CM_ "Toyota Yaris Hybrid 2014 (XP130, THS-II NoDSU) - reverse engineered from a candump (500kbps) captured on the";
CM_ "factory head-unit connector (28-pin, p/n 90980-12555, CAN-H=pin9/CAN-L=pin10), NOT the OBD-II diagnostic port.";
CM_ "Base messages taken from BogGyver/opendbc (tesla_unity_dev) toyota_nodsu_hybrid_pt_generated.dbc and empirically validated";
CM_ "against two independent real drive logs (re/data/logs/session_0044.log ~430s, session_0047.log ~440s). Additions for";
CM_ "BRAKE_ANALOG (0x224), COMBO_METER_0x34 (0x618), FUEL_COUNTER (0x3A0), HYBRID_STATUS/EV_DRIVE (0x498),";
CM_ "HV_BATTERY/BATTERY_SOC /BATTERY_CURRENT (0x49D), ICE_RUNNING (0x245 b3.4) and PWR_DEMAND (0x320) are original findings from this";
CM_ "project, not present in opendbc.";
CM_ "See re/docs/signal_findings.md for full validation methodology and confidence levels.";

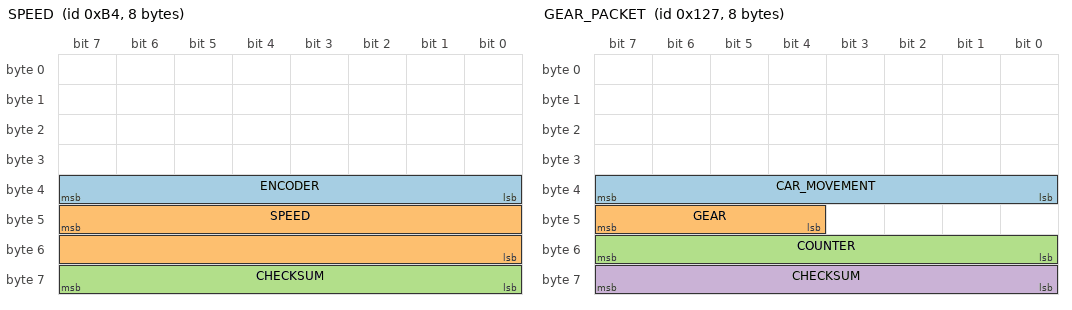
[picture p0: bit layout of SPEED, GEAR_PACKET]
BO_ 180 SPEED: 8 XXX
 SG_ ENCODER : 39|8@0+ (1,0) [0|255] "" XXX
 SG_ SPEED : 47|16@0+ (0.01,0) [0|250] "kph" XXX
 SG_ CHECKSUM : 63|8@0+ (1,0) [0|255] "" XXX

CM_ SG_ 180 SPEED "CONFIRMED. Validated against real 0->60->0 kph driving profile.";

BO_ 452 ENGINE_RPM: 8 XXX
 SG_ RPM : 7|16@0- (0.78125,0) [0|0] "rpm" XXX

CM_ SG_ 452 RPM "CONFIRMED. Oscillates 0/~1000-2000rpm matching ICE start/stop cycling typical of THS-II.";

BO_ 295 GEAR_PACKET: 8 XXX
 SG_ CAR_MOVEMENT : 39|8@0- (1,0) [0|255] "" XXX
 SG_ GEAR : 47|4@0+ (1,0) [0|15] "" XXX
 SG_ COUNTER : 55|8@0+ (1,0) [0|255] "" XXX
 SG_ CHECKSUM : 63|8@0+ (1,0) [0|255] "" XXX

VAL_ 295 GEAR 0 "P" 1 "R" 2 "N" 3 "D" 4 "B" ;
CM_ SG_ 295 GEAR "CONFIRMED, all 5 states observed across two independent logs: session_0044 shows a clean P(0)->R(1)->D(3) sequence with SPEED/BRAKE_PRESSED transitions lining up exactly with each shift; session_0047 adds N(2) and a full end-of-drive cycle through all five states including B (Engine Brake). CAR_MOVEMENT (byte4, signed) is a separate field in the same message, not part of the gear value.";

BO_ 560 BRAKE_MODULE2: 7 XXX
 SG_ BRAKE_PRESSED : 26|1@0+ (1,0) [0|1] "" XXX

CM_ SG_ 560 BRAKE_PRESSED "CONFIRMED. Transition timings correlate exactly with GEAR shifts and SPEED changes (brake held at standstill before/after each gear change).";

BO_ 548 BRAKE_ANALOG: 8 XXX
 SG_ BRAKE_VALUE : 32|16@0+ (1,0) [0|1023] "" XXX

CM_ BO_ 548 "STRONG HYPOTHESIS (not in any opendbc DBC). ID 0x224, ~41Hz. Formula: value = byte[4]<<8 | byte[5] (~10-bit, max observed 537). Median 0 while BRAKE_PRESSED=0 (n=12027) vs median 62 while pressed (n=5731); 99.99% of released samples <=5, 84% of pressed samples >5. Strong correlation confirms this is a brake pedal analog signal (pressure and/or position), but exact physical units/scale are NOT confirmed.";

BO_ 581 GAS_PEDAL: 8 XXX
 SG_ GAS_PEDAL : 23|8@0+ (0.005,0) [0|1] "" XXX
 SG_ ICE_RUNNING : 28|1@0+ (1,0) [0|1] "" XXX

CM_ SG_ 581 GAS_PEDAL "CONFIRMED. 0.0-0.35 (0-35%) range observed, closely tracking the accelerate/coast pattern of city driving and preceding each RPM/SPEED rise.";
CM_ SG_ 581 ICE_RUNNING "CONFIRMED on two independent logs. byte[3] bit4. 1 while the combustion engine is actually spinning (RPM>~800), 0 while stopped, INDEPENDENT of vehicle motion: 98-99% agreement with RPM(0x1C4)>50 across all four (moving/stopped x ICE on/off) states in both logs. Cleaner than thresholding RPM.";

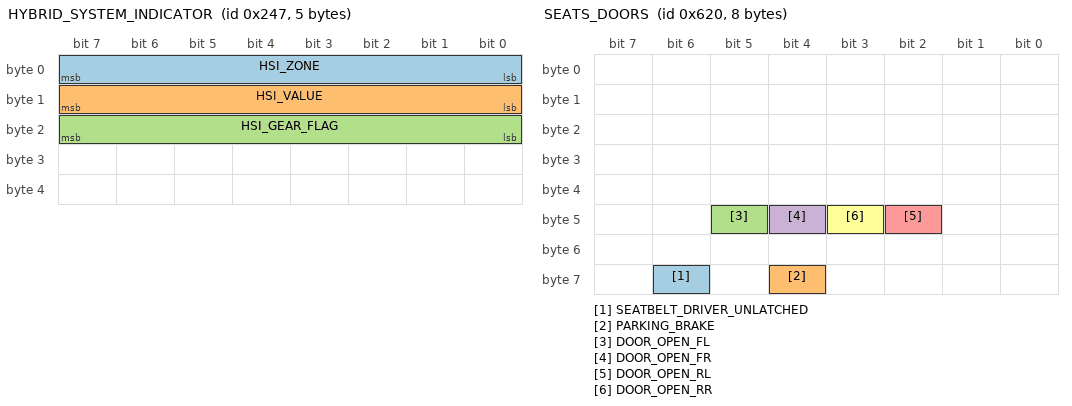
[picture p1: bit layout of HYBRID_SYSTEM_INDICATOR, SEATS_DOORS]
BO_ 583 HYBRID_SYSTEM_INDICATOR: 5 XXX
 SG_ HSI_ZONE : 7|8@0+ (1,0) [0|15] "" XXX
 SG_ HSI_VALUE : 15|8@0+ (1,0) [0|255] "%" XXX
 SG_ HSI_GEAR_FLAG : 23|8@0+ (1,0) [0|255] "" XXX

VAL_ 583 HSI_ZONE 4 "zero_in_gear" 6 "inactive_P_R" 12 "drive" 15 "charge" ;
VAL_ 583 HSI_GEAR_FLAG 50 "forward_gear" 255 "P_or_R" ;
CM_ BO_ 583 "CONFIRMED on two independent logs. ID 0x247, 42.5Hz, companion message of GAS_PEDAL (0x245). This is the dash CHG/ECO/PWR 'Hybrid System Indicator' value. HSI_VALUE (byte[1], sign per HSI_ZONE -- see SIGN NOTE below) = gauge position in percent of scale: 0 at standstill, +30..+47 at steady cruise (where the accel-like 0x320 byte4 sits at ~0 -- the discriminating test), up to +86/+94 observed under hard acceleration (full PWR = +100, never reached in these gentle drives), negative while coasting (-10..-19, light CHG) and braking, HARD-CLAMPED at -100 = full CHG. Always 0 in R and N, matching the real dash HSI which is inactive outside forward drive. HSI_ZONE (byte[0]): 12 on the PWR/ECO side, 15 on the CHG side, 4 when zero while in gear, 6 in P/R. HSI_GEAR_FLAG (byte[2]): 50 in forward gears, 255 in P/R. The exact ECO/PWR boundary is a fixed fraction of the positive scale on the real gauge (typically the top ~third); calibrate visually against the dash if pixel-exact zoning is needed. SIGN NOTE: HSI_ZONE, not HSI_VALUE's byte, carries the sign -- the two sides encode byte[1] differently and their raw ranges overlap. Zone 12 (PWR/ECO): byte[1] is an unsigned magnitude that sweeps past 155 under full throttle. Zone 15 (CHG): byte[1] is two's complement, hard-clamped at -100 (raw 156). Zones 4/6: always 0. The correlation is exact across both logs (n=32779). Inferring the sign from byte[1] alone -- either the DBC-nominal signed int8_t or the raw>=156 floor rule -- reads a hard-PWR value as deeply negative and swings the gauge to full CHG; confirmed on the car, hence the zone-based decode in firmware. DISPLAY NOTE: the dash halves the positive (PWR) value for display (PWR% = raw/2) because the ECO/PWR boundary (raw~100) is only the midpoint of the real gauge's PWR sweep, not its top -- see re/docs/signal_findings.md for the full caveat.";

BO_ 1090 CLIMATE_0x442: 8 XXX
 SG_ AMBIENT_TEMP : 7|8@0+ (1,-40) [-40|215] "degC" XXX

CM_ SG_ 1090 AMBIENT_TEMP "CONFIRMED. ID 0x442 (~2.5Hz, climate family 0x440/0x442/0x44D/0x45C), byte[0] - 40 = outside/ambient temperature in degC. The only byte that is quasi-constant (>95% single value) within each session but different across the two logs (raw 77 vs 67 -> 37degC vs 27degC); scale confirmed against the actual outside temperatures of the two capture days.";

BO_ 1553 UI_SETTING: 8 XXX
 SG_ UNITS : 26|2@0+ (1,0) [0|3] "" XXX
 SG_ ODOMETER : 43|20@0+ (1,0) [0|1048575] "" XXX

VAL_ 1553 UNITS 1 "km" 2 "miles" ;
CM_ SG_ 1553 ODOMETER "CONFIRMED but NOT remaining range. This is the TOTAL vehicle odometer (99552 -> 99555 km over the ~7min/~3km log, UNITS=km). No distance-to-empty / remaining-range signal was found on this bus -- see re/docs/signal_findings.md for the negative-result justification.";

BO_ 1556 STEERING_LEVERS: 8 XXX
 SG_ TURN_SIGNALS : 29|2@0+ (1,0) [0|3] "" XXX
 SG_ HAZARD_LIGHT : 27|1@0+ (1,0) [0|1] "" XXX

VAL_ 1556 TURN_SIGNALS 3 "none" 2 "right" 1 "left" ;
CM_ SG_ 1556 TURN_SIGNALS "CONFIRMED. All 3 states (left/right/none) observed over the drive with plausible multi-second durations consistent with real indicator usage at turns.";

BO_ 1568 SEATS_DOORS: 8 XXX
 SG_ SEATBELT_DRIVER_UNLATCHED : 62|1@0+ (1,0) [0|1] "" XXX
 SG_ PARKING_BRAKE : 60|1@0+ (1,0) [0|1] "" XXX
 SG_ DOOR_OPEN_FL : 45|1@0+ (1,0) [0|1] "" XXX
 SG_ DOOR_OPEN_FR : 44|1@0+ (1,0) [0|1] "" XXX
 SG_ DOOR_OPEN_RL : 42|1@0+ (1,0) [0|1] "" XXX
 SG_ DOOR_OPEN_RR : 43|1@0+ (1,0) [0|1] "" XXX

CM_ BO_ 1568 "CONFIRMED PRESENT, plausible (seatbelt toggles 0/1); doors never opened during this particular drive so DOOR_OPEN_* only show constant 0 in this log (not independently validated, but the message/bit layout is inherited verbatim from opendbc).";

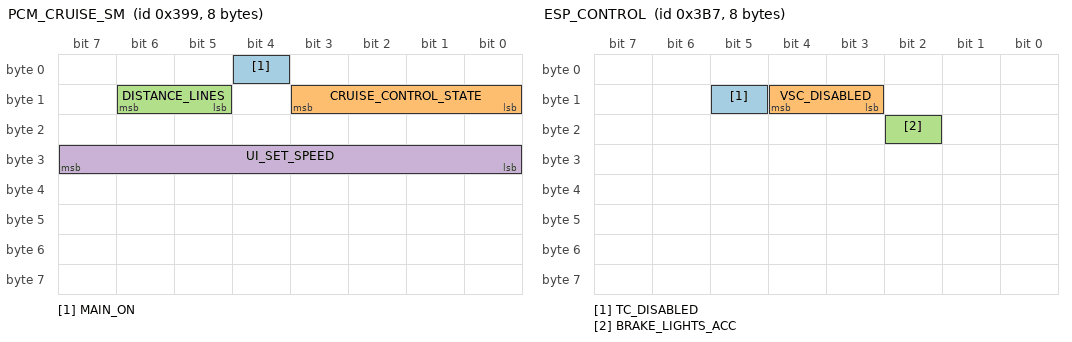
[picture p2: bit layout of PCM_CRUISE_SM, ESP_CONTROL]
BO_ 921 PCM_CRUISE_SM: 8 XXX
 SG_ MAIN_ON : 4|1@0+ (1,0) [0|1] "" XXX
 SG_ CRUISE_CONTROL_STATE : 11|4@0+ (1,0) [0|15] "" XXX
 SG_ DISTANCE_LINES : 14|2@0+ (1,0) [0|3] "" XXX
 SG_ UI_SET_SPEED : 31|8@0+ (1,0) [0|255] "" XXX

CM_ BO_ 921 "PRESENT but INACTIVE for the whole log (all-zero) -- cruise control was never engaged during capture, so fields could not be behaviourally validated beyond confirming the message exists at the expected ID/layout.";

BO_ 951 ESP_CONTROL: 8 XXX
 SG_ TC_DISABLED : 13|1@0+ (1,0) [0|1] "" XXX
 SG_ VSC_DISABLED : 12|2@0+ (1,0) [0|1] "" XXX
 SG_ BRAKE_LIGHTS_ACC : 18|1@0+ (1,0) [0|1] "" XXX

CM_ BO_ 951 "PRESENT but INACTIVE for the whole log (no VSC/TC intervention occurred during this calm drive).";

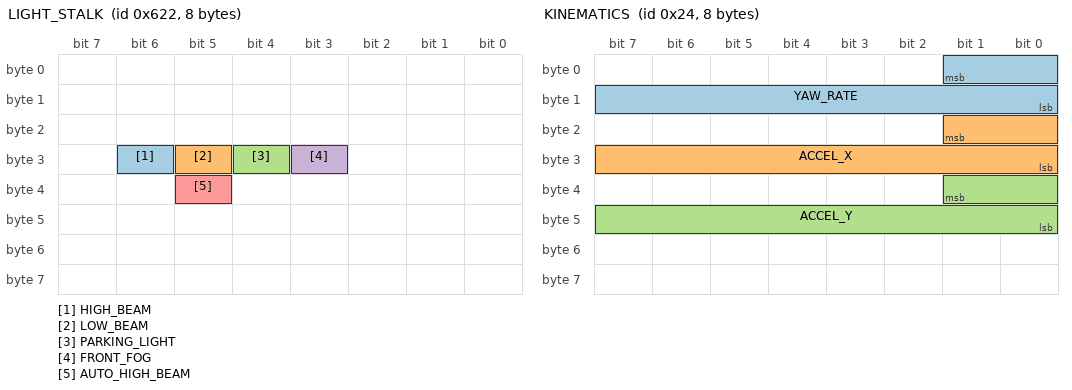
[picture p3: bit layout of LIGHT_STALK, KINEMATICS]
BO_ 1570 LIGHT_STALK: 8 XXX
 SG_ HIGH_BEAM : 30|1@0+ (1,0) [0|1] "" XXX
 SG_ LOW_BEAM : 29|1@0+ (1,0) [0|1] "" XXX
 SG_ PARKING_LIGHT : 28|1@0+ (1,0) [0|1] "" XXX
 SG_ FRONT_FOG : 27|1@0+ (1,0) [0|1] "" XXX
 SG_ AUTO_HIGH_BEAM : 37|1@0+ (1,0) [0|1] "" XXX

CM_ BO_ 1570 "CONFIRMED PRESENT; LOW_BEAM/PARKING_LIGHT toggled 0/1 during the log, plausible.";

BO_ 1560 COMBO_METER_0x34: 8 XXX
 SG_ TEMP_RAW : 24|8@0+ (1,0) [0|255] "" XXX

CM_ BO_ 1560 "STRONG HYPOTHESIS (not in any opendbc DBC). ID 0x618 belongs to a family of low-frequency (~0.1Hz) 'combination meter' multiplex messages (0x610-0x615, 0x618-0x61c). byte[3] (TEMP_RAW here) climbs monotonically and smoothly from 0 at cold start/idle to a plateau around 230-240 by t=350-430s, in lock-step with the engine running -- the textbook shape of an engine coolant warm-up curve reaching thermostat-regulated operating temperature after ~5 minutes. Candidate formula (UNCONFIRMED SCALE): temp_C = TEMP_RAW * 0.375, placing the plateau at a plausible 90 deg C; this scale factor is a best-fit guess, not derived from a reference thermometer reading. Could equally be transmission/CVT fluid temperature rather than coolant.";

BO_ 928 FUEL_COUNTER: 8 XXX
 SG_ FUEL_COUNTER_RAW : 63|8@0+ (1,0) [0|255] "" XXX

CM_ BO_ 928 "STRONG HYPOTHESIS (not in any opendbc DBC; NOT a fuel level gauge, see re/docs/signal_findings.md). ID 0x3A0 byte[7], only non-zero byte, 10Hz. Decrements correlate with ICE-ON RUNTIME (1 unit per ~20-25s of engine running, consistent to ~7% across both logs), not with wall time or distance; it even flickers 58<->59 while parked with the engine off. A 36L-tank level on a byte scale would deplete 15-20x slower than observed, so this is NOT the fuel gauge level, nor 'distance to empty' (km/unit via ODOMETER mismatches 7x between logs while time/unit is consistent to ~7%). Best hypothesis: a decrementing high-resolution fuel-consumed counter, quantum ~10-30mL, most likely the LOW BYTE of a wider register (would wrap 0->255 on a >=30min log -- logs so far are too short to confirm). Useful as instantaneous fuel consumption; do NOT use as absolute tank level.";

BO_ 953 TEMP_RAW2: 3 XXX
 SG_ TEMP2_RAW : 7|8@0+ (1,0) [0|255] "" XXX

CM_ BO_ 953 "STRONG HYPOTHESIS (not in any opendbc DBC). ID 0x3B9, dlc=3, byte[1] and byte[2] always 0x00 -- only byte[0] (TEMP2_RAW) is active, transmitted at ~1Hz. In both independent logs byte[0] climbs smoothly and nearly monotonically from a stable starting value early in the drive to a plateau late in the drive (session_0044: 103->173 over ~430s; session_0047: 110->160 over ~440s). Correlates very strongly with elapsed time (r=0.945/0.968) AND with the already-confirmed TEMP_RAW (0x618 byte3) warm-up curve (r=0.950/0.969), including a shared inflection point where both curves flatten out. Weak/negative correlation with instantaneous RPM (r=-0.16/-0.10) rules out a fast-responding signal and rules out battery voltage (which would sag in discharge and spike in regen, not climb monotonically); consistent with a second, more thermally-lagged temperature sensor -- candidate: engine oil, CVT/transaxle fluid, or HV battery pack. Plateau value differs between the two logs (173 vs 160), unlike coolant temp which is thermostat-regulated to a fixed setpoint. Not distinguishable from this data alone which physical sensor this is; no scale/formula proposed.";

BO_ 1186 CHASSIS_BRAKE2: 8 XXX
 SG_ BRAKE2_FIELD_A : 31|8@0+ (1,0) [0|255] "" XXX
 SG_ BRAKE2_FIELD_B : 47|8@0+ (1,0) [0|255] "" XXX

CM_ BO_ 1186 "TENTATIVE (not in any opendbc DBC) -- explicitly NOT a battery/SOC candidate despite superficially matching a charge/discharge pattern. ID 0x4A2, byte[3] (BRAKE2_FIELD_A) and byte[5] (BRAKE2_FIELD_B) both correlate strongly with the already-confirmed BRAKE_ANALOG (0x224 byte[4:6]): byte[3] r=-0.93/-0.79, byte[5] r=+0.93/+0.79 across the two logs -- far stronger than their correlation with GAS_PEDAL. Also correlates with SPEED (byte[3] r=+0.60/+0.22), which a pure battery-power signal would not be expected to do. Most likely a second brake/deceleration-related telemetry pair from a different ECU (e.g. ABS/VSC wheel-brake pressure), not battery power. Recorded here so this ID is not re-investigated as a false-lead SOC candidate.";

BO_ 1176 HYBRID_STATUS: 8 XXX
 SG_ EV_DRIVE : 47|1@0+ (1,0) [0|1] "" XXX

CM_ SG_ 1176 EV_DRIVE "CONFIRMED on two independent logs. byte[5] bit7. ON (100%) only while the vehicle is moving with the ICE stopped (pure electric propulsion, including regen); OFF while stopped even with ICE off (0-11% residual, hysteresis around standstill transitions) and OFF while driving with ICE running (3-9%, transition lag). Matches dash 'EV' indicator semantics; found by exhaustive per-bit agreement scan against the proxy RPM<50 AND speed>1 (23/23 and 5/5 proxy transitions matched). Redundant inverse 'ICE stopped' bits also validated: 0x49C byte[5] bit6 and 0x4AD byte[3] bit6. Message family 0x498-0x4AF exists in commaai opendbc toyota_2017_ref_pt.dbc as opaque CGW (gateway) data-recorder frames ENG1D50..ENG1D60 / DRENGxx, and is ABSENT on the non-hybrid 2010 Camry (TUCRRC analysis) -- a hybrid-powertrain-specific telemetry family.";

BO_ 1181 HV_BATTERY: 8 XXX
 SG_ BATTERY_CURRENT : 23|8@0- (2,0) [-256|254] "A" XXX
 SG_ BATTERY_SOC : 41|6@0+ (2,0) [0|126] "%" XXX

CM_ SG_ 1181 BATTERY_SOC "CONFIRMED on two independent logs, scale derived (not yet checked against a diagnostic tool). ID 0x49D (~2Hz, hybrid data-recorder family via gateway, see 0x498). 6-bit field: byte[5] bits 1..0 (MSBs) + byte[6] bits 7..4, * 2 = HV battery SOC in %. It is a coulomb counter: every step lines up with a fixed amount of integrated BATTERY_CURRENT (~235 raw-count-seconds per step, 11 consecutive steps within +-10% in session_0044), rises under regen, falls in EV drive. Observed 58-80% (raw 29-40), starting at 60% in both drive logs and 68% in the mode-button capture. With BATTERY_CURRENT at 2 A/bit one step is 0.13 Ah = 2% of the 6.5 Ah pack. byte[5] bits 3..2 are a separate 2-bit state. The next two 6-bit fields (byte[6] bits 3..0 + byte[7] bits 7..6, and byte[7] bits 5..0) follow the SOC with an offset and are unidentified.";
CM_ SG_ 1181 BATTERY_CURRENT "CONFIRMED on two independent logs as HV pack current, scale derived. byte[2] signed, positive = discharge. ~0 parked, about -23 during stationary warm-up charging, +25..+32 in EV acceleration, down to -54 in hard regen. 2 A/bit from the energy balance against vehicle kinetic energy: at 1 A/bit the pack would deliver less energy than the car gains during EV acceleration. byte[0]/byte[1] (~95 at rest, up to ~118 under charge current, down under discharge) behave like two pack-voltage readings, scale unknown. byte[3] low 7 bits and byte[4] rise slowly over a drive (temperature candidates).";
CM_ "0x4A7 byte[2] was this project's first SOC decode and is NOT the SOC: it rises whenever the engine runs (+0.36..0.42 raw/s) and falls whenever it is stopped (-0.2 raw/s moving, -0.05 at standstill), including through hard regenerative braking (down 68 times, up once), and starts at raw 108 in all three captures. byte[3] top 2 bits are its fraction. An engine-side quantity that decays faster with airflow -- probably a modelled exhaust/catalyst temperature. Unidentified.";
CM_ "0x612 byte[5]: excluded as SOC -- slow random walk centered on 128 with no charge/discharge physics, sign-flipping correlation with time between the two logs; byte[1] alternates 0x80/0x00 (heartbeat). Unidentified (possibly a 12V-battery current with offset 128). 0x4AE byte[7] (72-75, slowly rising in both logs): weak, unconfirmed candidate for HV battery/inverter temperature. 0x619 byte[6] and 0x63B byte[6]: also excluded (unstable/heartbeat-like).";

BO_ 800 PWR_DEMAND: 8 XXX
 SG_ ACCEL_DEMAND : 39|8@0- (1,0) [-128|127] "" XXX
 SG_ ACCEL_DEMAND_OFFSET_COPY : 63|8@0- (1,0) [-128|127] "" XXX

CM_ BO_ 800 "STRONG HYPOTHESIS on semantics, scale unconfirmed. ID 0x320, ~20Hz. byte[4] as signed 8-bit: positive under acceleration demand (+10..+31 with pedal), negative while braking/coasting (-8..-48), ~0 at rest AND at steady cruise -- a longitudinal acceleration/torque-demand-like quantity, NOT HV battery current (stays positive during EV traction and does not go negative during stationary charging; the real battery current is 0x49D byte[2]). byte[7] tracks byte[4]+42 (same signal, constant offset); byte[5] is a {0,8} flag active only at standstill. Together with EV_DRIVE (0x498), ICE_RUNNING (0x245) and BATTERY_SOC (0x49D), this fully explains how the Simplesoft RP5-TY-101 canbus box synthesizes its 'OilElectricityInfo' energy-flow display from pure passive listening -- no active diagnostic polling needed.";

CM_ "=== Added by the full capture survey (see re/docs/capture_survey.md). Layouts verified on both drive logs unless marked otherwise. ===";

BO_ 36 KINEMATICS: 8 XXX
 SG_ YAW_RATE : 1|10@0+ (0.245,-125.44) [-125|125] "deg/s" XXX
 SG_ ACCEL_X : 17|10@0+ (0.03589,-18.375) [-18|18] "m/s2" XXX
 SG_ ACCEL_Y : 33|10@0+ (0.03589,-18.375) [-18|18] "m/s2" XXX

CM_ BO_ 36 "0x024, 82 Hz. YAW_RATE (raw-512) tracks speed*steering angle at r=0.994/0.997; its scale comes from ACCEL_Y = v*yaw. ACCEL_Y uses the opendbc scale and matches v*yaw at r=0.89/0.85. ACCEL_X (opendbc calls this field STEERING_TORQUE on other models) follows d(speed)/dt at r=0.95 in session_0044 with the same 0.036 m/s2 per bit; weaker (0.63) in session_0047, which has bus gaps.";

BO_ 37 STEER_ANGLE_SENSOR: 8 XXX
 SG_ STEER_ANGLE : 3|12@0- (1.5,0) [-3072|3070] "deg" XXX

CM_ BO_ 37 "0x025, 82 Hz. Steering-wheel angle, 1.5 deg/bit, observed -491..+500 deg. Bytes 4-6 take only multiples of 10 (10..130) and are not the opendbc STEER_RATE/STEER_FRACTION fields; unidentified.";

BO_ 676 SPEED_2: 5 XXX
 SG_ SPEED : 7|16@0+ (0.01,0) [0|250] "kph" XXX

CM_ BO_ 676 "0x2A4, 20 Hz. Same value as SPEED (0x0B4), R2=0.9995. byte[4] is a checksum.";

BO_ 851 MG2_SPEED: 2 XXX
 SG_ MG2_RPM : 7|16@0- (1,0) [-32768|32767] "rpm" XXX

CM_ BO_ 851 "0x353, 4 Hz. Signed, 77 per km/h, negative in reverse. Read as traction-motor (MG2) rpm at 1 rpm/bit: that gives 77 rpm per km/h, and together with MG1_RPM it reproduces the transaxle's 2.636 MG2 reduction (MG2/ring = 77/29.3 = 2.63). Scale not checked against a tool.";

BO_ 865 PEDAL_SPEED_0x361: 4 XXX
 SG_ SPEED_SIGNED : 15|8@0- (1.31,0) [-168|166] "kph" XXX
 SG_ GAS_PEDAL_RAW : 23|8@0+ (0.005,0) [0|1] "" XXX

CM_ BO_ 865 "0x361, 15.5 Hz. byte[1] signed speed (0.76 per km/h, negative in reverse), byte[2] identical to GAS_PEDAL raw (0x245 byte[2]). byte[0] bit0 set in reverse.";

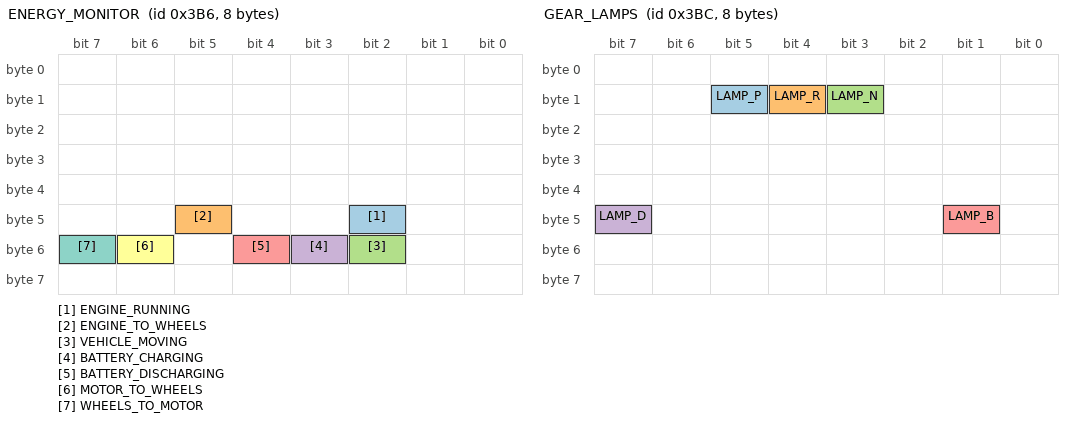
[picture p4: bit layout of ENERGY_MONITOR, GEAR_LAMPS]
BO_ 950 ENERGY_MONITOR: 8 XXX
 SG_ ENGINE_RUNNING : 42|1@0+ (1,0) [0|1] "" XXX
 SG_ ENGINE_TO_WHEELS : 45|1@0+ (1,0) [0|1] "" XXX
 SG_ VEHICLE_MOVING : 50|1@0+ (1,0) [0|1] "" XXX
 SG_ BATTERY_CHARGING : 51|1@0+ (1,0) [0|1] "" XXX
 SG_ BATTERY_DISCHARGING : 52|1@0+ (1,0) [0|1] "" XXX
 SG_ MOTOR_TO_WHEELS : 54|1@0+ (1,0) [0|1] "" XXX
 SG_ WHEELS_TO_MOTOR : 55|1@0+ (1,0) [0|1] "" XXX

CM_ BO_ 950 "0x3B6, 1 Hz. STRONG HYPOTHESIS: the flow flags behind the cluster's energy monitor. byte[6] takes one fixed pattern per driving state on both logs: 0x75 EV drive, 0xAD regen, 0x6D/0x6C engine driving and charging, 0x0C engine only, 0x01 standstill. BATTERY_CHARGING / BATTERY_DISCHARGING agree with the sign of BATTERY_CURRENT 95-97% of the time; ENGINE_RUNNING (byte[5] bits 2-3) agrees with RPM 93-98%. The individual bit names are read off those patterns and have not been checked against the car's own display.";

BO_ 956 GEAR_LAMPS: 8 XXX
 SG_ LAMP_P : 13|1@0+ (1,0) [0|1] "" XXX
 SG_ LAMP_R : 12|1@0+ (1,0) [0|1] "" XXX
 SG_ LAMP_N : 11|1@0+ (1,0) [0|1] "" XXX
 SG_ LAMP_D : 47|1@0+ (1,0) [0|1] "" XXX
 SG_ LAMP_B : 41|1@0+ (1,0) [0|1] "" XXX

CM_ BO_ 956 "0x3BC, 1 Hz. One bit per shift position; P, R and D agree with GEAR (0x127) 98-100% on both logs. N and B only occur in session_0047 (a few frames each).";

BO_ 979 FUEL_FLOW: 2 XXX
 SG_ FUEL_FLOW : 7|16@0+ (0.975,0) [0|63896] "mm3/s" XXX

CM_ BO_ 979 "0x3D3, 2 Hz. Zero with the engine off. Fuel flow: INSTANT_CONSUMPTION (0x610) * speed is proportional to it (r=0.96, same constant on both logs). The scale follows from reading INSTANT_CONSUMPTION as 0.1 l/100km and is as unconfirmed as that one; 1 mm3/s per bit is the round value next to it.";

BO_ 1561 RANGE_0x619: 8 XXX
 SG_ RANGE_TO_EMPTY : 47|16@0+ (1,0) [0|65535] "km" XXX

CM_ BO_ 1561 "0x619, 0.1 Hz. HYPOTHESIS, three captures. byte[5:6] reads 290->287 km over session_0044, 263->262 over session_0047 and 185 in the mode-button capture; against the odometer that is 24 km of range for 21 km driven and 77 for 73.";

BO_ 1190 FUEL_LEVEL_0x4A6: 8 XXX
 SG_ FUEL_LEVEL : 39|8@0+ (0.5,0) [0|127] "l" XXX

CM_ BO_ 1190 "0x4A6, 1.3 Hz. HYPOTHESIS, three points. byte[4] is constant within each capture and falls across them (36, 34, 26), one step per ~9.5 km. 0.5 l/bit is a guess that gives 5 l/100km between captures and agrees with RANGE_TO_EMPTY.";

BO_ 1178 MG1_SPEED: 8 XXX
 SG_ MG1_RPM : 7|16@0- (0.625,0) [-20480|20480] "rpm" XXX

CM_ BO_ 1178 "0x49A, 2 Hz. Signed 16-bit that is a linear mix of engine rpm and vehicle speed (raw = 5.75*RPM - 122*kph, R2=0.997-0.998): the generator (MG1) on the power-split device. 0.625 rpm/bit assumes the 3.6 planetary factor (MG1 = 3.6*ICE - 2.6*ring). Spins backwards in EV drive.";

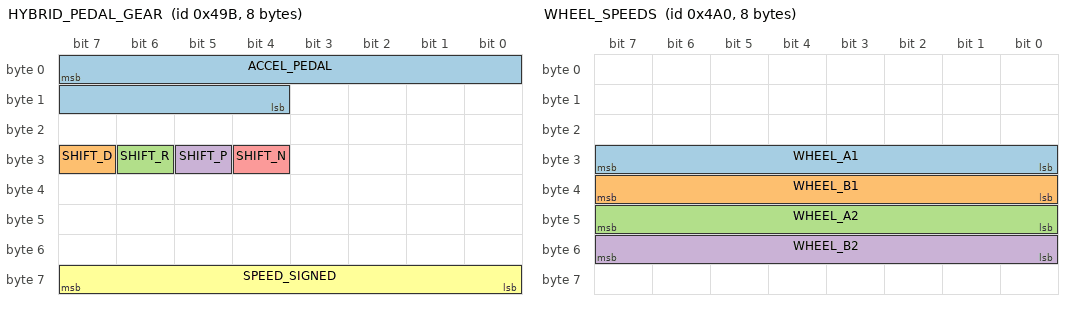
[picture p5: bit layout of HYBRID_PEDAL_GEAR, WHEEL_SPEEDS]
BO_ 1179 HYBRID_PEDAL_GEAR: 8 XXX
 SG_ ACCEL_PEDAL : 7|12@0+ (0.025,0) [0|102] "%" XXX
 SG_ SHIFT_D : 31|1@0+ (1,0) [0|1] "" XXX
 SG_ SHIFT_R : 30|1@0+ (1,0) [0|1] "" XXX
 SG_ SHIFT_P : 29|1@0+ (1,0) [0|1] "" XXX
 SG_ SHIFT_N : 28|1@0+ (1,0) [0|1] "" XXX
 SG_ SPEED_SIGNED : 63|8@0- (1,0) [-128|127] "kph" XXX

CM_ BO_ 1179 "0x49B, 2 Hz. ACCEL_PEDAL is a 12-bit copy of GAS_PEDAL (R2=0.998); the 0.025 scale lines it up with GAS_PEDAL in percent. Shift bits agree with GEAR 97-100%. SPEED_SIGNED is whole km/h, negative in reverse.";

BO_ 1180 ENGINE_STATUS: 8 XXX
 SG_ ICE_STOPPED : 46|1@0+ (1,0) [0|1] "" XXX
 SG_ ENGINE_POWER : 63|8@0+ (0.5,0) [0|127] "kW" XXX

CM_ BO_ 1180 "0x49C, 2 Hz. ICE_STOPPED is the exact inverse of ICE running (100% on both logs). ENGINE_POWER (byte[7]) is zero with the engine off and follows an engine-power estimate (traction + drag + battery charging) at r=0.94/0.93; 0.5 kW/bit is approximate (fitted slope 1.5-1.9 per kW). byte[1] and byte[2] behave the same way and may be the requested values. 0x4AE byte[2] is a near copy of byte[7].";

BO_ 1184 WHEEL_SPEEDS: 8 XXX
 SG_ WHEEL_A1 : 31|8@0+ (1.3,0) [0|331] "kph" XXX
 SG_ WHEEL_B1 : 39|8@0+ (1.3,0) [0|331] "kph" XXX
 SG_ WHEEL_A2 : 47|8@0+ (1.3,0) [0|331] "kph" XXX
 SG_ WHEEL_B2 : 55|8@0+ (1.3,0) [0|331] "kph" XXX

CM_ BO_ 1184 "0x4A0, 2 Hz. Four per-wheel speeds, coarse (0.77 counts per km/h). The A-B difference within each pair follows the steering angle (r=0.73-0.87), so A and B are opposite sides of the car, and A1/A2 are the same side. Which side is left and which pair is the front axle is not established.";

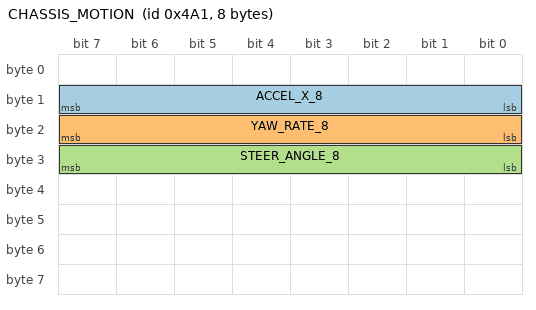
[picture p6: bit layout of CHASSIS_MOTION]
BO_ 1185 CHASSIS_MOTION: 8 XXX
 SG_ ACCEL_X_8 : 15|8@0- (1,0) [-128|127] "" XXX
 SG_ YAW_RATE_8 : 23|8@0+ (1.04,-133.1) [-133|132] "deg/s" XXX
 SG_ STEER_ANGLE_8 : 31|8@0+ (9.2,-1177.6) [-1178|1168] "deg" XXX

CM_ BO_ 1185 "0x4A1, 2 Hz. Low-rate 8-bit copies of the 0x024/0x025 values: byte[2] yaw rate (r=0.995), byte[3] steering angle (r=0.998), both offset by 128; byte[1] signed longitudinal acceleration (r=0.96 in session_0044).";

BO_ 1552 COMBO_METER_0x610: 8 XXX
 SG_ DISPLAY_SPEED : 23|8@0+ (1,0) [0|255] "kph" XXX
 SG_ INSTANT_CONSUMPTION : 47|16@0+ (0.1,0) [0|6553.5] "l/100km" XXX

CM_ BO_ 1552 "0x610, 2 Hz. DISPLAY_SPEED is whole km/h, 1:1 with SPEED (0x0B4). INSTANT_CONSUMPTION (byte[5:6]) is 0 while moving with the engine off, 0xFFFD at standstill and 6-365 while the engine runs. It is consumption per distance: value * speed = 3.51 * FUEL_FLOW (0x3D3) with the same constant on both logs (r=0.96). The 0.1 l/100km scale is not confirmed against the car, but it makes FUEL_FLOW come out at 0.975 mm3/s per bit, one fuel-counter step (0x3A0) at 15-21 ml, and the whole of session_0044 (cold start, EV stretches included) at 4.9 l/100km.";

BO_ 1564 TRIP_INFO_0x61C: 8 XXX
 SG_ TRIP_MINUTES : 63|8@0+ (1,0) [0|255] "min" XXX

CM_ BO_ 1564 "0x61C, 0.1 Hz. byte[7] increments exactly every 60 s on both logs: elapsed trip time in minutes.";

CM_ SG_ 1568 PARKING_BRAKE "HYPOTHESIS, one log. byte[7] bit4 (opendbc layout). In session_0047 it is set from the start, clears 1 s before the hybrid system goes READY and 8 s before the car first moves, and sets again right after the final stop. Never set in session_0044. In the same log a door bit (byte[5] bit4) is set until t=69 s, and the driver seatbelt bit clears at t=95 s and sets again at t=418 s.";
CM_ SG_ 1560 TEMP_RAW "REVISED: probably not coolant temperature. byte[3] moves in steps of 10, starts at 0, and in session_0047 falls again (130 -> 110) within a minute of the car stopping, which a coolant temperature cannot do. It behaves like a trip average, most likely average speed, but no scale fits both logs.";
CM_ "0x49D byte[0]/byte[1] (HV_BATTERY): two readings that rise under charge current and sag under discharge, ~95 at rest. Pack voltage with unknown scale; roughly 1.66 V/bit if the rested pack sits at a NiMH-typical 1.32 V/cell. 0x38B byte[5] and 0x4AE byte[5] are linear functions of it.";
CM_ "IDs 0x2FC, 0x387, 0x389, 0x38E, 0x38F, 0x434, 0x435, 0x443, 0x458, 0x6F9 appear only in the captures taken with the Simplesoft box in line (session_0047, mode-button capture) and carry constant data: frames from the box, not from the car.";

CM_ SG_ 1090 AMBIENT_TEMP "WRONG: reads 37 before READY and 27 after on a 7 degC November morning. A state byte. Outside-temperature candidate instead: 0x3B0 byte[3] - 50 (57 at 7 degC, 76-82 in July).";
CM_ "=== SIGNALS NOT ON THIS BUS (see re/docs/signal_findings.md for full explanation) ===";
CM_ "Remaining range: see RANGE_TO_EMPTY (0x619), found later; the earlier conclusion that it is not broadcast was wrong.";
CM_ "HV battery current is on 0x49D byte[2] (see BATTERY_CURRENT). The Prius Gen2/Gen3-style 0x03B/0x3CB/0x3CD/0x529 IDs are absent on this platform.";
